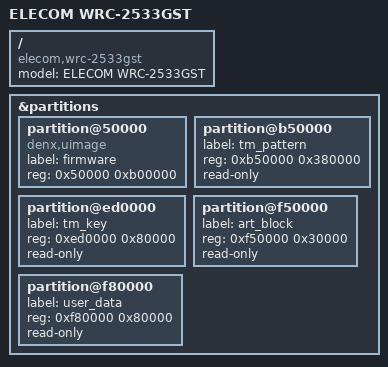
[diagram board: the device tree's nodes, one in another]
/dts-v1/;

#include "mt7621_elecom_wrc-gst.dtsi"

/ {
	compatible = "elecom,wrc-2533gst", "mediatek,mt7621-soc";
	model = "ELECOM WRC-2533GST";
};

&partitions {
	partition@50000 {
		compatible = "denx,uimage";
		label = "firmware";
		reg = <0x50000 0xb00000>;
	};

	partition@b50000 {
		label = "tm_pattern";
		reg = <0xb50000 0x380000>;
		read-only;
	};

	partition@ed0000 {
		label = "tm_key";
		reg = <0xed0000 0x80000>;
		read-only;
	};

	partition@f50000 {
		label = "art_block";
		reg = <0xf50000 0x30000>;
		read-only;
	};

	partition@f80000 {
		label = "user_data";
		reg = <0xf80000 0x80000>;
		read-only;
	};
};
